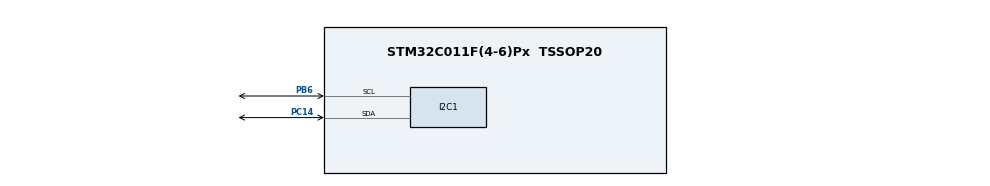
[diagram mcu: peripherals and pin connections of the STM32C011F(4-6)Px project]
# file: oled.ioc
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I2C1.Timing=0x20303E5D
Mcu.Family=STM32C0
Mcu.Name=STM32C011F(4-6)Px
Mcu.Package=TSSOP20
PA13.Mode=Serial_Wire
PA13.Signal=DEBUG_SWDIO
PA14-BOOT0.Mode=Serial_Wire
PA14-BOOT0.Signal=DEBUG_SWCLK
PB6.Mode=I2C
PB6.Signal=I2C1_SCL
PC14-OSCX_IN\ (PC14).Mode=I2C
PC14-OSCX_IN\ (PC14).Signal=I2C1_SDA
ProjectManager.HeapSize=0x200
ProjectManager.StackSize=0x400
ProjectManager.TargetToolchain=STM32CubeIDE
RCC.ADCFreq_Value=48000000
RCC.AHBFreq_Value=48000000
RCC.CortexFreq_Value=48000000
RCC.EXTERNAL_CLOCK_VALUE=12288000
RCC.HCLKFreq_Value=48000000
RCC.HSE_VALUE=8000000
RCC.HSISYSCLKDivider=RCC_HSI_DIV1
RCC.HSI_VALUE=48000000
RCC.LSE_VALUE=32768
RCC.SYSCLKFreq_VALUE=48000000
board=custom

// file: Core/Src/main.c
/* USER CODE BEGIN Header */
/**
  ******************************************************************************
  * @file           : main.c
  * @brief          : Main program body
  ******************************************************************************
  * @attention
  *
  * Copyright (c) 2024 STMicroelectronics.
  * All rights reserved.
  *
  * This software is licensed under terms that can be found in the LICENSE file
  * in the root directory of this software component.
  * If no LICENSE file comes with this software, it is provided AS-IS.
  *
  ******************************************************************************
  */
/* USER CODE END Header */
#include "main.h"
#include "ssd1306.h"
#include "ssd1306_fonts.h"

I2C_HandleTypeDef hi2c1;

/* USER CODE BEGIN PV */

const unsigned char franzininho_128x64 [] = {
		0xff, 0xff, 0xff, 0xff, 0xff, 0xff, 0xff, 0xff, 0xff, 0xff, 0xff, 0xff, 0xff, 0xff, 0xff, 0xff,
		0xff, 0xff, 0xff, 0xff, 0xff, 0xff, 0xff, 0xff, 0xff, 0xff, 0xff, 0xff, 0xff, 0xff, 0xff, 0xff,
		0xff, 0xff, 0xff, 0xff, 0xff, 0xff, 0xff, 0xff, 0xff, 0xff, 0xff, 0xff, 0xff, 0xff, 0xff, 0xff,
		0xff, 0xff, 0xff, 0xff, 0xff, 0xff, 0xff, 0xff, 0xff, 0xff, 0xff, 0xff, 0xfc, 0x7f, 0xff, 0xff,
		0xff, 0xff, 0xff, 0xff, 0xff, 0xff, 0xff, 0xff, 0xff, 0xff, 0xff, 0xff, 0xf0, 0x1f, 0xff, 0xff,
		0xff, 0xff, 0xff, 0xff, 0xff, 0xff, 0xff, 0xff, 0xff, 0xff, 0xff, 0xff, 0xc3, 0x87, 0xff, 0xff,
		0xff, 0xff, 0xff, 0xff, 0xff, 0xff, 0xff, 0xff, 0xff, 0xff, 0xff, 0xff, 0x08, 0xe1, 0xff, 0xff,
		0xff, 0xff, 0xff, 0xff, 0xff, 0xff, 0xff, 0xff, 0xff, 0xff, 0xff, 0xfc, 0x32, 0x38, 0xff, 0xff,
		0xff, 0xff, 0xff, 0xff, 0xff, 0xff, 0xff, 0xff, 0xff, 0xff, 0xff, 0xf1, 0xc7, 0x81, 0xff, 0xff,
		0xff, 0xff, 0xff, 0xff, 0xff, 0xff, 0xff, 0xe3, 0xff, 0xff, 0xff, 0xc7, 0xff, 0xc3, 0xff, 0xff,
		0xff, 0xff, 0xff, 0xff, 0xff, 0xff, 0xff, 0x00, 0xff, 0xff, 0xff, 0x0c, 0xff, 0x0f, 0xff, 0xff,
		0xff, 0xff, 0xff, 0xff, 0xff, 0xff, 0xf8, 0x3c, 0x3f, 0xff, 0xfc, 0x31, 0xfc, 0x3f, 0xff, 0xff,
		0xff, 0xff, 0xff, 0xff, 0xff, 0xff, 0xe1, 0xff, 0x1f, 0xff, 0xf1, 0xc7, 0xf0, 0xff, 0xff, 0xff,
		0xff, 0xff, 0xff, 0xff, 0xff, 0xff, 0x07, 0xff, 0xc7, 0xff, 0xc3, 0x1f, 0xc3, 0xff, 0xff, 0xff,
		0xff, 0xff, 0xff, 0xff, 0xff, 0xfc, 0x1f, 0xff, 0xe1, 0xff, 0x0c, 0x7f, 0x0f, 0xff, 0xff, 0xff,
		0xff, 0xff, 0xff, 0xff, 0xff, 0xe0, 0xff, 0xff, 0xf8, 0x7e, 0x11, 0xfc, 0x7f, 0xff, 0xff, 0xff,
		0xff, 0xff, 0xff, 0xff, 0xff, 0x87, 0xff, 0xff, 0xfe, 0x7e, 0x07, 0xf1, 0xff, 0xff, 0xff, 0xff,
		0xff, 0xff, 0xff, 0xff, 0xfc, 0x1f, 0xff, 0xff, 0xff, 0xf8, 0xe1, 0xc7, 0xff, 0xff, 0xff, 0xff,
		0xff, 0xff, 0xff, 0xff, 0xf0, 0x7f, 0xff, 0xff, 0xff, 0xe3, 0xf8, 0x1f, 0xff, 0xff, 0xff, 0xff,
		0xff, 0xff, 0xff, 0xff, 0x83, 0x3f, 0xff, 0xff, 0xff, 0xcf, 0xf0, 0x7f, 0xff, 0xff, 0xff, 0xff,
		0xff, 0xff, 0xff, 0xfe, 0x1f, 0x8f, 0xff, 0xff, 0xff, 0x9f, 0xc7, 0xff, 0xff, 0xff, 0xff, 0xff,
		0xff, 0xff, 0xff, 0xf0, 0xff, 0xe3, 0xff, 0xff, 0xff, 0x3e, 0x1f, 0xff, 0xff, 0xff, 0xff, 0xff,
		0xff, 0xff, 0xff, 0xc3, 0xff, 0xf8, 0xff, 0xff, 0xfe, 0x00, 0xff, 0xff, 0xff, 0xff, 0xff, 0xff,
		0xff, 0xff, 0xfe, 0x0f, 0xff, 0xfe, 0x03, 0xff, 0xfe, 0x07, 0xf7, 0xff, 0xff, 0xff, 0xff, 0xff,
		0xff, 0xff, 0xf0, 0x07, 0xff, 0xfe, 0x38, 0xff, 0xff, 0xff, 0xe1, 0xff, 0xff, 0xff, 0xff, 0xff,
		0xff, 0xff, 0xc3, 0xe3, 0xff, 0xfe, 0x7e, 0x7f, 0xff, 0xff, 0xf8, 0xff, 0xff, 0xff, 0xff, 0xff,
		0xff, 0xff, 0xc3, 0xf9, 0xff, 0xff, 0x7c, 0x7f, 0xff, 0xff, 0xfc, 0x7f, 0xff, 0xff, 0xff, 0xff,
		0xff, 0xff, 0xf1, 0xfc, 0x7f, 0xff, 0x81, 0xff, 0xff, 0xff, 0xfe, 0x1f, 0xff, 0xff, 0xff, 0xff,
		0xff, 0xff, 0xfc, 0x7f, 0x1f, 0xff, 0xff, 0xff, 0xff, 0xff, 0xff, 0x87, 0xff, 0xff, 0xff, 0xff,
		0xff, 0xff, 0xfe, 0x1f, 0xcf, 0xff, 0xff, 0xff, 0xff, 0xff, 0xff, 0xe3, 0xff, 0xff, 0xff, 0xff,
		0xff, 0xff, 0xff, 0x87, 0xf3, 0xf8, 0x1f, 0xff, 0xff, 0xff, 0xff, 0xf1, 0xff, 0xff, 0xff, 0xff,
		0xff, 0xff, 0xff, 0xe3, 0xf8, 0x63, 0xcf, 0xff, 0xff, 0xff, 0xff, 0xf8, 0x7f, 0xff, 0xff, 0xff,
		0xff, 0xff, 0xff, 0xf1, 0xff, 0x07, 0xe7, 0xff, 0xff, 0xff, 0xff, 0xfe, 0x3f, 0xff, 0xff, 0xff,
		0xff, 0xff, 0xff, 0xfc, 0x7f, 0xe3, 0xcf, 0xff, 0xff, 0xc0, 0xff, 0xff, 0x1f, 0xff, 0xff, 0xff,
		0xff, 0xff, 0xff, 0xfe, 0x1f, 0xf8, 0x3f, 0xff, 0xff, 0x1e, 0x7f, 0xfc, 0x1f, 0xff, 0xff, 0xff,
		0xff, 0xff, 0xff, 0xff, 0x8f, 0xff, 0xff, 0xc3, 0xff, 0x3f, 0x3f, 0xf0, 0x7f, 0xff, 0xff, 0xff,
		0xff, 0xff, 0xff, 0xff, 0xe3, 0xff, 0xff, 0x00, 0xff, 0x9e, 0x7f, 0x83, 0xff, 0xff, 0xff, 0xff,
		0xff, 0xff, 0xff, 0xff, 0xf0, 0xff, 0xfe, 0x3e, 0x7f, 0xc1, 0xfe, 0x1f, 0xff, 0xff, 0xff, 0xff,
		0xff, 0xff, 0xff, 0xff, 0xfc, 0x7f, 0xfe, 0x3c, 0x7f, 0xe3, 0xf0, 0x7f, 0xff, 0xff, 0xff, 0xff,
		0xff, 0xff, 0xff, 0xff, 0xfe, 0x1f, 0xfc, 0x00, 0xff, 0xc7, 0x83, 0xff, 0xff, 0xff, 0xff, 0xff,
		0xff, 0xff, 0xff, 0xff, 0xff, 0x87, 0xe1, 0xff, 0xff, 0x1e, 0x1f, 0xff, 0xff, 0xff, 0xff, 0xff,
		0xff, 0xff, 0xff, 0xff, 0xff, 0xe3, 0x87, 0xff, 0xf8, 0x70, 0x7f, 0xff, 0xff, 0xff, 0xff, 0xff,
		0xff, 0xff, 0xff, 0xff, 0xff, 0xf0, 0x3f, 0xff, 0xe3, 0xc3, 0xff, 0xff, 0xff, 0xff, 0xff, 0xff,
		0xff, 0xff, 0xff, 0xff, 0xff, 0xfc, 0x7f, 0xff, 0x1e, 0x1f, 0xff, 0xff, 0xff, 0xff, 0xff, 0xff,
		0xff, 0xff, 0xff, 0xff, 0xff, 0xff, 0x1f, 0xf8, 0x70, 0x7f, 0xff, 0xff, 0xff, 0xff, 0xff, 0xff,
		0xff, 0xff, 0xff, 0xff, 0xff, 0xff, 0x87, 0xe3, 0xc3, 0xff, 0xff, 0xff, 0xff, 0xff, 0xff, 0xff,
		0xff, 0xff, 0xff, 0xff, 0xff, 0xff, 0xe1, 0x0e, 0x0f, 0xff, 0xff, 0xff, 0xff, 0xff, 0xff, 0xff,
		0xff, 0xff, 0xff, 0xff, 0xff, 0xff, 0xf8, 0x70, 0x7f, 0xff, 0xff, 0xff, 0xff, 0xff, 0xff, 0xff,
		0xff, 0xff, 0xff, 0xff, 0xff, 0xff, 0xfc, 0x03, 0xff, 0xff, 0xff, 0xff, 0xff, 0xff, 0xff, 0xff,
		0xff, 0xff, 0xff, 0xff, 0xff, 0xff, 0xfe, 0x0f, 0xff, 0xff, 0xff, 0xff, 0xff, 0xff, 0xff, 0xff,
		0xff, 0xff, 0xff, 0xff, 0xff, 0xff, 0xff, 0xff, 0xff, 0xff, 0xff, 0xff, 0xff, 0xff, 0xff, 0xff,
		0xff, 0xff, 0xff, 0xff, 0xff, 0xff, 0xff, 0xff, 0xff, 0xff, 0xff, 0xff, 0xff, 0xff, 0xff, 0xff,
		0xff, 0xff, 0xff, 0xff, 0xff, 0xff, 0xff, 0xff, 0xff, 0xff, 0xff, 0xff, 0xff, 0xff, 0xff, 0xff,
		0xff, 0xff, 0xff, 0xff, 0xff, 0xff, 0xff, 0xff, 0xff, 0xff, 0xff, 0xff, 0xff, 0xff, 0xff, 0xff,
		0xff, 0x00, 0x60, 0x07, 0x00, 0xc7, 0xcc, 0x01, 0x91, 0xf9, 0x39, 0xf9, 0x9f, 0x98, 0x03, 0xff,
		0xff, 0x3f, 0xc7, 0xe4, 0x7c, 0xc1, 0xcf, 0xe7, 0x90, 0x79, 0x38, 0x79, 0x9f, 0x99, 0xf9, 0xff,
		0xff, 0x20, 0xc0, 0x0c, 0x7c, 0xce, 0x4f, 0x9f, 0x93, 0x99, 0x3b, 0x89, 0x80, 0x13, 0xfd, 0xff,
		0xff, 0x3f, 0xc6, 0x1c, 0x00, 0xcf, 0x0e, 0x3f, 0x93, 0xc1, 0x3b, 0xe1, 0x9f, 0x99, 0xf9, 0xff,
		0xff, 0x3f, 0xef, 0x8c, 0xfe, 0xcf, 0xcc, 0x01, 0x93, 0xf3, 0xbb, 0xfb, 0x9f, 0xbc, 0x03, 0xff,
		0xff, 0xff, 0xff, 0xff, 0xff, 0xff, 0xff, 0xff, 0xff, 0xff, 0xff, 0xff, 0xff, 0xff, 0xff, 0xff,
		0xff, 0xff, 0xff, 0xff, 0xff, 0xff, 0xff, 0xff, 0xff, 0xff, 0xff, 0xff, 0xff, 0xff, 0xff, 0xff,
		0xff, 0xff, 0xff, 0xff, 0xff, 0xff, 0xff, 0xff, 0xff, 0xff, 0xff, 0xff, 0xff, 0xff, 0xff, 0xff,
		0xff, 0xff, 0xff, 0xff, 0xff, 0xff, 0xff, 0xff, 0xff, 0xff, 0xff, 0xff, 0xff, 0xff, 0xff, 0xff,
		0xff, 0xff, 0xff, 0xff, 0xff, 0xff, 0xff, 0xff, 0xff, 0xff, 0xff, 0xff, 0xff, 0xff, 0xff, 0xff
	};

/* USER CODE END PV */

void SystemClock_Config(void);
static void MX_GPIO_Init(void);
static void MX_I2C1_Init(void);

int main(void)
{

  /* MCU Configuration--------------------------------------------------------*/

  /* Reset of all peripherals, Initializes the Flash interface and the Systick. */
  HAL_Init();

  /* Configure the system clock */
  SystemClock_Config();

  /* Initialize all configured peripherals */
  MX_GPIO_Init();
  MX_I2C1_Init();
  /* USER CODE BEGIN 2 */
  ssd1306_Init();
  /* USER CODE END 2 */

  /* Infinite loop */
  while (1)
  {

    /* USER CODE BEGIN 3 */
	ssd1306_Fill(Black);
	ssd1306_SetCursor(4, 4);
	ssd1306_WriteString("Portal", Font_11x18, White);
	ssd1306_SetCursor(4, 24);
	ssd1306_WriteString("Embarcados", Font_11x18, White);
	ssd1306_UpdateScreen();
	HAL_Delay(1000);
	ssd1306_DrawBitmap(0,0,franzininho_128x64,128,64, White);
	ssd1306_UpdateScreen();
	HAL_Delay(1000);
  }
  /* USER CODE END 3 */
}

void SystemClock_Config(void)
{
  RCC_OscInitTypeDef RCC_OscInitStruct = {0};
  RCC_ClkInitTypeDef RCC_ClkInitStruct = {0};

  /** Initializes the RCC Oscillators according to the specified parameters
  * in the RCC_OscInitTypeDef structure.
  */
  RCC_OscInitStruct.OscillatorType = RCC_OSCILLATORTYPE_HSI;
  RCC_OscInitStruct.HSIState = RCC_HSI_ON;
  RCC_OscInitStruct.HSIDiv = RCC_HSI_DIV1;
  RCC_OscInitStruct.HSICalibrationValue = RCC_HSICALIBRATION_DEFAULT;
  if (HAL_RCC_OscConfig(&RCC_OscInitStruct) != HAL_OK)
  {
    Error_Handler();
  }

  /** Initializes the CPU, AHB and APB buses clocks
  */
  RCC_ClkInitStruct.ClockType = RCC_CLOCKTYPE_HCLK|RCC_CLOCKTYPE_SYSCLK
                              |RCC_CLOCKTYPE_PCLK1;
  RCC_ClkInitStruct.SYSCLKSource = RCC_SYSCLKSOURCE_HSI;
  RCC_ClkInitStruct.SYSCLKDivider = RCC_SYSCLK_DIV1;
  RCC_ClkInitStruct.AHBCLKDivider = RCC_HCLK_DIV1;
  RCC_ClkInitStruct.APB1CLKDivider = RCC_APB1_DIV1;

  if (HAL_RCC_ClockConfig(&RCC_ClkInitStruct, FLASH_LATENCY_1) != HAL_OK)
  {
    Error_Handler();
  }
}

static void MX_I2C1_Init(void)
{

  hi2c1.Instance = I2C1;
  hi2c1.Init.Timing = 0x20303E5D;
  hi2c1.Init.OwnAddress1 = 0;
  hi2c1.Init.AddressingMode = I2C_ADDRESSINGMODE_7BIT;
  hi2c1.Init.DualAddressMode = I2C_DUALADDRESS_DISABLE;
  hi2c1.Init.OwnAddress2 = 0;
  hi2c1.Init.OwnAddress2Masks = I2C_OA2_NOMASK;
  hi2c1.Init.GeneralCallMode = I2C_GENERALCALL_DISABLE;
  hi2c1.Init.NoStretchMode = I2C_NOSTRETCH_DISABLE;
  if (HAL_I2C_Init(&hi2c1) != HAL_OK)
  {
    Error_Handler();
  }

  /** Configure Analogue filter
  */
  if (HAL_I2CEx_ConfigAnalogFilter(&hi2c1, I2C_ANALOGFILTER_ENABLE) != HAL_OK)
  {
    Error_Handler();
  }

  /** Configure Digital filter
  */
  if (HAL_I2CEx_ConfigDigitalFilter(&hi2c1, 0) != HAL_OK)
  {
    Error_Handler();
  }

}

static void MX_GPIO_Init(void)
{

  /* GPIO Ports Clock Enable */
  __HAL_RCC_GPIOC_CLK_ENABLE();
  __HAL_RCC_GPIOA_CLK_ENABLE();
  __HAL_RCC_GPIOB_CLK_ENABLE();

}

void Error_Handler(void)
{
  __disable_irq();
  while (1)
  {
  }
}
